AUTOSAR XML (schema 4.0)
package /VehicleProject  # Complete Vehicle Electronic System
package /VehicleProject/ECUs
  ecu configuration EngineECU: ecu=ENG_ECU_01, ecu-extract=EngineSystem  # Engine Control Unit - Primary ECU
    ecu partition ApplicationPartition: ecu-extract=EngineSystem
    ecu partition DiagnosticPartition: ecu-extract=DiagnosticSystem
    module config Can
    module config CanIf
    module config Com
    module config PduR
    module config NvM
    module config Dcm
    module config Dem
  ecu configuration TransmissionECU: ecu=TRANS_ECU_01, ecu-extract=TransmissionSystem  # Transmission Control Unit
    module config Can
    module config Com
  ecu configuration BodyECU: ecu=BODY_ECU_01, ecu-extract=BodySystem  # Body Control Module
    module config Lin
    module config Dio
package /VehicleProject/SoftwareComponents
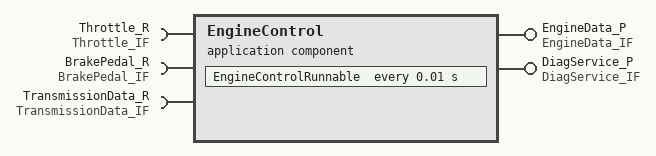
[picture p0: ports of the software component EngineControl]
  application sw component type EngineControl  # Engine Management Controller
    provide port EngineData_P: provided-interface=EngineData_IF
    provide port DiagService_P: provided-interface=DiagService_IF
    require port Throttle_R: required-interface=Throttle_IF
    require port BrakePedal_R: required-interface=BrakePedal_IF
    require port TransmissionData_R: required-interface=TransmissionData_IF
    behavior EngineControlBehavior
      timing event EngineControl_10ms: start-on-event=EngineControlRunnable, period=0.01
      runnable EngineControlRunnable: runs-inside-exclusive-area=EngineControlArea
      exclusive area EngineControlArea
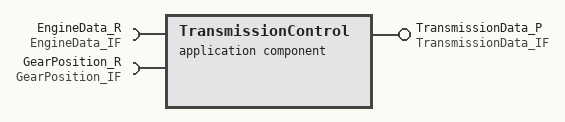
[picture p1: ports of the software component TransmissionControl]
  application sw component type TransmissionControl  # Transmission Management Controller
    provide port TransmissionData_P: provided-interface=TransmissionData_IF
    require port EngineData_R: required-interface=EngineData_IF
    require port GearPosition_R: required-interface=GearPosition_IF
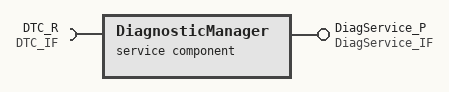
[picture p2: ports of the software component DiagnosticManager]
  service sw component type DiagnosticManager  # Diagnostic Services Manager
    provide port DiagService_P: provided-interface=DiagService_IF
    require port DTC_R: required-interface=DTC_IF
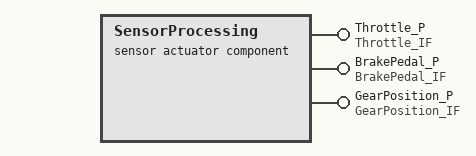
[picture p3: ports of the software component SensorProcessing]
  sensor actuator sw component type SensorProcessing  # Sensor Data Acquisition and Processing
    provide port Throttle_P: provided-interface=Throttle_IF
    provide port BrakePedal_P: provided-interface=BrakePedal_IF
    provide port GearPosition_P: provided-interface=GearPosition_IF
  composition sw component type VehicleComposition  # Top Level Vehicle Software Composition
    4 x component:
      EngineControlInstance: type=EngineControl
      TransmissionControlInstance: type=TransmissionControl
      SensorProcessingInstance: type=SensorProcessing
      DiagnosticManagerInstance: type=DiagnosticManager
    connect SensorProcessingInstance.Throttle_P -> EngineControlInstance.Throttle_R
    connect SensorProcessingInstance.BrakePedal_P -> EngineControlInstance.BrakePedal_R
    connect EngineControlInstance.EngineData_P -> TransmissionControlInstance.EngineData_R
    connect SensorProcessingInstance.GearPosition_P -> TransmissionControlInstance.GearPosition_R
package /VehicleProject/Interfaces
  6 x sender receiver interface:
    EngineData_IF
      data EngineRPM: type=uint16
      data EngineTemp: type=sint16
      data EngineLoad: type=uint8
    Throttle_IF
      data ThrottlePosition: type=uint8
      data ThrottleFault: type=boolean
    BrakePedal_IF
      data BrakePedalPosition: type=uint8
      data BrakePressed: type=boolean
    TransmissionData_IF
      data CurrentGear: type=uint8
      data TransmissionTemp: type=sint16
      data TransmissionTorque: type=uint16
    GearPosition_IF
      data GearSensorPosition: type=uint8
    DTC_IF
      data DTC_Code: type=uint32
      data DTC_Status: type=uint8
  client server interface DiagService_IF
    operation ReadDTC
      arg DTC_ID: type=uint32, direction=IN
      arg DTC_Data: type=uint8, direction=OUT
    operation ClearDTC
      arg ClearResult: type=boolean, direction=OUT
package /VehicleProject/DataTypes
  6 x app type:
    boolean: category=BOOLEAN
    uint8: category=VALUE
    uint16: category=VALUE
    uint32: category=VALUE
    sint8: category=VALUE
    sint16: category=VALUE
package /VehicleProject/System
  system mapping VehicleSystemMapping
    4 x swc to ecu mapping:
      EngineControlMapping: component=EngineControlInstance, ecu=EngineECU
      TransmissionControlMapping: component=TransmissionControlInstance, ecu=TransmissionECU
      DiagnosticManagerMapping: component=DiagnosticManagerInstance, ecu=EngineECU
      SensorProcessingMapping: component=SensorProcessingInstance, ecu=EngineECU
